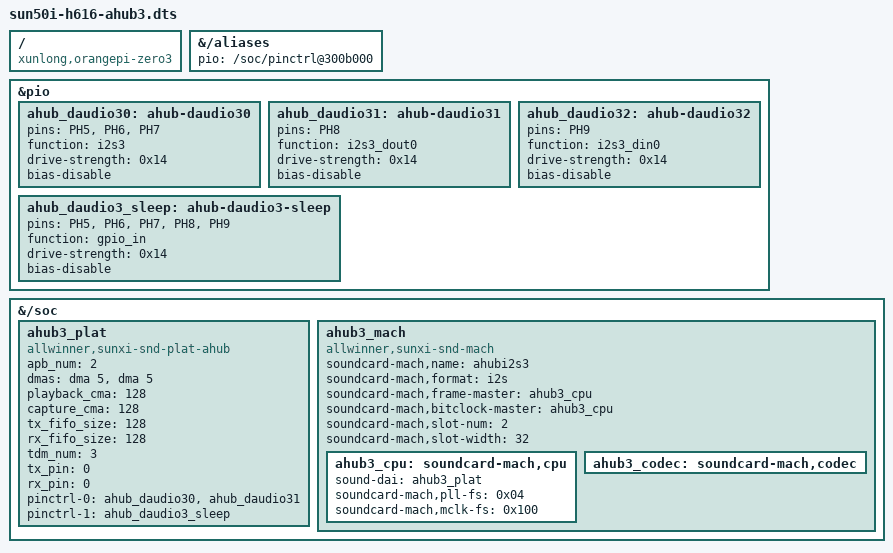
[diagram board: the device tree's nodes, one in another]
/dts-v1/;
/plugin/;

/ {
	compatible = "xunlong,orangepi-zero3", "allwinner,sun50i-h616";
	fragment@0 {
		target-path = "/aliases";
		__overlay__ {
			pio = "/soc/pinctrl@300b000";
		};
	};

	fragment@1 {
		target = <&pio>;
		__overlay__ {
			ahub_daudio30:ahub-daudio30 {
				pins = "PH5", "PH6", "PH7";
				function = "i2s3";
				drive-strength = <0x14>;
				bias-disable;			
			};
			ahub_daudio31:ahub-daudio31 {
				pins = "PH8";
				function = "i2s3_dout0";
				drive-strength = <0x14>;
				bias-disable;
			};
			ahub_daudio32:ahub-daudio32 {
				pins = "PH9";
				function = "i2s3_din0";
				drive-strength = <0x14>;
				bias-disable;
			};
			ahub_daudio3_sleep:ahub-daudio3-sleep {
				pins = "PH5", "PH6", "PH7", "PH8", "PH9";
				function = "gpio_in";
				drive-strength = <0x14>;
				bias-disable;
			};
		};
	};

	fragment@2 {
		target-path = "/soc";
		__overlay__ {
			ahub3_plat:ahub3_plat {
				#sound-dai-cells = <0>;
				compatible	= "allwinner,sunxi-snd-plat-ahub";
				apb_num		= <2>;	/* for dma port 5 */
				dmas		= <&dma 5>, <&dma 5>;
				dma-names	= "tx", "rx";
				playback_cma	= <128>;
				capture_cma	= <128>;
				tx_fifo_size	= <128>;
				rx_fifo_size	= <128>;

				tdm_num		= <3>;
				tx_pin		= <0>;
				rx_pin		= <0>;
				status		= "okay";

				//pinctrl_used;
				pinctrl-names = "default", "sleep";

				pinctrl-0 = <&ahub_daudio30>, <&ahub_daudio31>;
				pinctrl-1 = <&ahub_daudio3_sleep>;
			};
			ahub3_mach:ahub3_mach {
				compatible = "allwinner,sunxi-snd-mach";
				soundcard-mach,name = "ahubi2s3";
				soundcard-mach,format		= "i2s";
				soundcard-mach,frame-master	= <&ahub3_cpu>;
				soundcard-mach,bitclock-master	= <&ahub3_cpu>;
				/* soundcard-mach,frame-inversion; */
				/* soundcard-mach,bitclock-inversion; */
				soundcard-mach,slot-num		= <2>;
				soundcard-mach,slot-width	= <32>;
				status = "okay";
				ahub3_cpu: soundcard-mach,cpu {
					sound-dai = <&ahub3_plat>;
					soundcard-mach,pll-fs	= <0x04>;
					soundcard-mach,mclk-fs	= <0x100>;
				};

				ahub3_codec: soundcard-mach,codec {					
				};
			};
		};
	};
};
